VERSION ""

NS_ :

BS_:

BU_: BMS

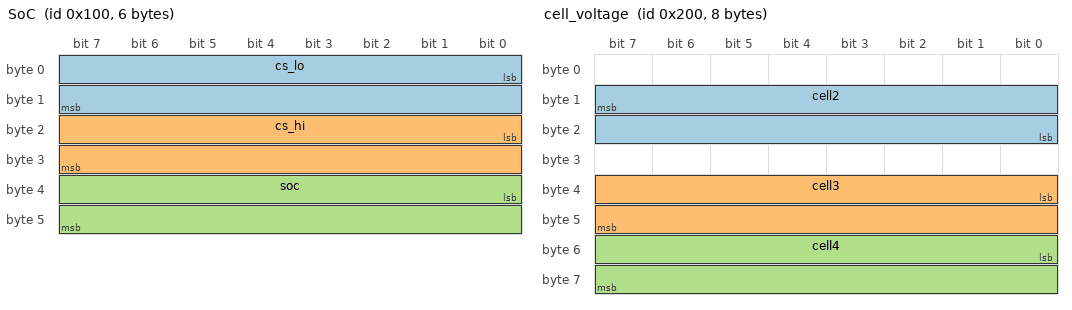
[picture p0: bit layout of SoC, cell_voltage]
BO_ 256 SoC: 6 BMS
 SG_ cs_lo : 0|16@1- (0.1,0) [0|0] "A" Vector__XXX
 SG_ cs_hi : 16|16@1- (0.1,0) [0|0] "A" Vector__XXX
 SG_ soc : 32|16@1+ (0.1,0) [0|0] "%" Vector__XXX

BO_ 512 cell_voltage: 8 BMS
 SG_ cell1 : -1|16@0+ (1,0) [0|0] "" Vector__XXX
 SG_ cell2 : 15|16@0+ (1,0) [0|0] "" Vector__XXX
 SG_ cell3 : 32|16@1+ (1,0) [0|0] "" Vector__XXX
 SG_ cell4 : 48|16@1+ (1,0) [0|0] "" Vector__XXX
